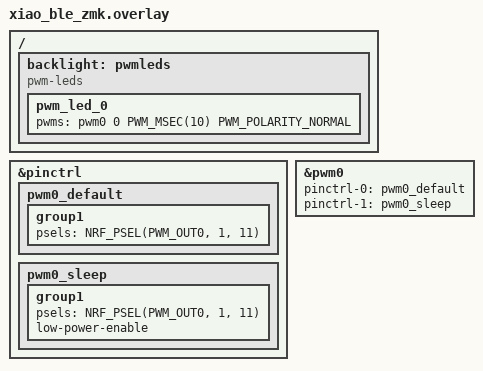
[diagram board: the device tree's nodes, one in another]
/ {
    backlight: pwmleds {
        compatible = "pwm-leds";
        pwm_led_0 {
            pwms = <&pwm0 0 PWM_MSEC(10) PWM_POLARITY_NORMAL>;
        };
    };
};

&pinctrl {
    // ST7789's LCD_BL is connected to P1.11 (D6) pinout
    pwm0_default: pwm0_default {
        group1 {
            psels = <NRF_PSEL(PWM_OUT0, 1, 11)>;
        };
    };
    pwm0_sleep: pwm0_sleep {
        group1 {
            psels = <NRF_PSEL(PWM_OUT0, 1, 11)>;
            low-power-enable;
        };
    };
};

&pwm0 {
    status = "okay";
    pinctrl-0 = <&pwm0_default>;
    pinctrl-1 = <&pwm0_sleep>;
    pinctrl-names = "default", "sleep";
};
